# DDRSS0_PHY_CFG register map
Vendor: Texas Instruments
Registers are 32-bit, access per field, reset 0x0 unless marked. A register's access mark holds for its fields unless they carry their own. Offsets are as the file gives them; [hi:lo] are bit positions; lines under a group give offsets from that group; {n}, {i} and the like mark numbered series.

## DDRSS0_PHY_CFG (part 2 of 2)
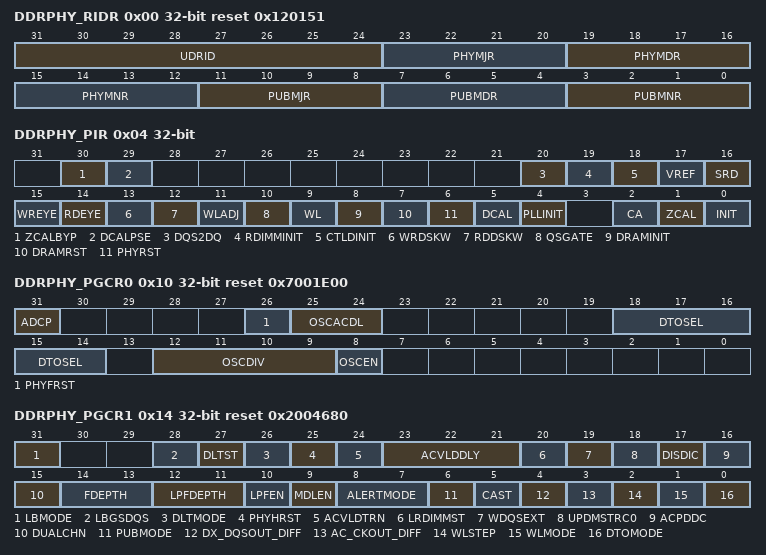
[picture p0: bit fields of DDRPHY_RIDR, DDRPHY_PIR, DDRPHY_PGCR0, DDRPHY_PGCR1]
0x00 DDRPHY_RIDR ro reset 0x120151 — Revision Identification Register
  [31:24] UDRID — User-Defined Revision ID
  [23:20] PHYMJR — PHY Major Revision
  [19:16] PHYMDR — PHY Moderate Revision
  [15:12] PHYMNR — PHY Minor Revision
  [11:8] PUBMJR — PUB Major Revision
  [7:4] PUBMDR — PUB Moderate Revision
  [3:0] PUBMNR — PUB Minor Revision
0x04 DDRPHY_PIR access not given — PHY Initialization Register
  [30] ZCALBYP — Impedance Calibration Bypass (access RW1C)
  [29] DCALPSE — Digital Delay Line (DDL) Calibration Pause (access RW1C)
  [20] DQS2DQ rw — Write DQS2DQ Training
  [19] RDIMMINIT rw — RDIMM Initialization
  [18] CTLDINIT rw — Controller DRAM Initialization
  [17] VREF rw — VREF Training
  [16] SRD rw — Static Read Training
  [15] WREYE rw — Write Data Eye Training
  [14] RDEYE rw — Read Data Eye Training
  [13] WRDSKW rw — Write Data Bit Deskew
  [12] RDDSKW rw — Read Data Bit Deskew
  [11] WLADJ rw — Write Leveling Adjust
  [10] QSGATE rw — Read DQS Gate Training
  [9] WL rw — Write Leveling
  [8] DRAMINIT rw — DRAM Initialization
  [7] DRAMRST rw — DRAM Reset (DDR3/DDR4/LPDDR4 Only)
  [6] PHYRST rw — PHY Reset
  [5] DCAL rw — Digital Delay Line (DDL) Calibration
  [4] PLLINIT rw — PLL Initialiazation
  [2] CA rw — CA Training
  [1] ZCAL rw — Impedance Calibration
  [0] INIT — Initialization Trigger (access RW1C)
0x10 DDRPHY_PGCR0 reset 0x7001E00 — PHY General Configuration Register 0
  [31] ADCP rw — Address Copy
  [26] PHYFRST rw — PHY FIFO Reset
  [25:24] OSCACDL rw — Oscillator Mode Address/Command Delay Line Select
  [18:14] DTOSEL rw — Digital Test Output Select
  [12:9] OSCDIV rw — Oscillator Mode Division
  [8] OSCEN rw — Oscillator Enable
0x14 DDRPHY_PGCR1 access not given reset 0x2004680 — PHY General Configuration Register 1
  [31] LBMODE rw — Loopback Mode
  [28] LBGSDQS — Load GSDQS LCDL with 2x the calibrated GSDQSPRD value (equivalent to one CK period) (access RW1C)
  [27] DLTST rw — Delay Line Test Start
  [26] DLTMODE rw — Delay Line Test Mode
  [25] PHYHRST rw — PHY High-Speed Reset
  [24] ACVLDTRN rw — AC Loopback Valid Train
  [23:21] ACVLDDLY rw — AC Loopback Valid Delay
  [20] LRDIMMST rw — LRDIMM Software Training
  [19] WDQSEXT rw — When WDQS Extension mode is enabled by setting this bit to 1'b1
  [18] UPDMSTRC0 rw — DFI Update Master Channel 0
  [17] DISDIC rw — Enable/Disable control for dfi_init_complete.
  [16] ACPDDC rw — AC Power-Down with Dual Channels
  [15] DUALCHN rw — Dual Channel Configuration
  [14:13] FDEPTH rw — Filter Depth
  [12:11] LPFDEPTH rw — Low-Pass Filter Depth
  [10] LPFEN rw — Low-Pass Filter Enable
  [9] MDLEN rw — Master Delay Line Enable
  [8:7] ALERTMODE rw — Control dfi_alert_n signal sent to the memory controller
  [6] PUBMODE rw — Enables, if set, the PUB to control the interface to the PHY and SDRAM.
  [5] CAST rw — CA Software Training.
  [4] DX_DQSOUT_DIFF rw — Selects PDIFF cell for DQS generation
  [3] AC_CKOUT_DIFF rw — Selects PDIFF cell for CK generation
  [2] WLSTEP rw — Write Leveling Step
  [1] WLMODE rw — Write Leveling (Software) Mode
  [0] DTOMODE rw — Digital Test Output Mode
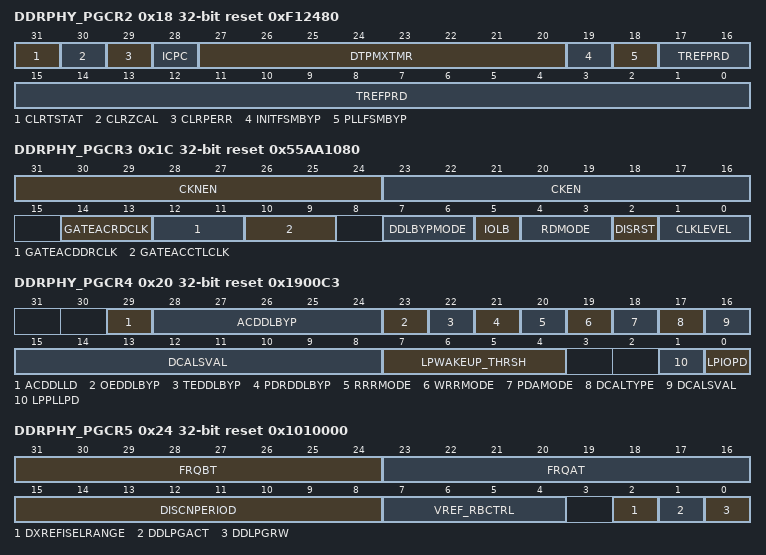
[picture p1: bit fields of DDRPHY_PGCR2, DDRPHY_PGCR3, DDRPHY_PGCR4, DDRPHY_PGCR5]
0x18 DDRPHY_PGCR2 access not given reset 0xF12480 — PHY General Configuration Register 2
  [31] CLRTSTAT — Clear Training Status Registers (access RW1C)
  [30] CLRZCAL — Clear Impedance Calibration (access RW1C)
  [29] CLRPERR — Clear Parity Error (access RW1C)
  [28] ICPC rw — Initialization Complete Pin Configuration
  [27:20] DTPMXTMR rw — Data Training PUB Mode Exit Timer
  [19] INITFSMBYP rw — Initialization Bypass
  [18] PLLFSMBYP rw — PLL FSM Bypass
  [17:0] TREFPRD rw — Refresh Period
0x1C DDRPHY_PGCR3 reset 0x55AA1080 — PHY General Configuration Register 3
  [31:24] CKNEN rw — CKN Enable
  [23:16] CKEN rw — CK Enable
  [14:13] GATEACRDCLK rw — Enable Clock Gating for AC [0] ctl_rd_clk
  [12:11] GATEACDDRCLK rw — Enable Clock Gating for AC [0] ddr_clk
  [10:9] GATEACCTLCLK rw — Enable Clock Gating for AC [0] ctl_clk
  [7:6] DDLBYPMODE rw — Controls DDL Bypass Modes
  [5] IOLB rw — IO Loop-Back Select
  [4:3] RDMODE rw — AC Receive FIFO Read Mode
  [2] DISRST rw — Read FIFO Reset Disable
  [1:0] CLKLEVEL rw — Clock Level when Clock Gating
0x20 DDRPHY_PGCR4 reset 0x1900C3 — PHY General Configuration Register 4
  [29] ACDDLLD rw — AC DDL Delay Select Dymainc Load
  [28:24] ACDDLBYP rw — AC DDL Bypass
  [23] OEDDLBYP rw — AC OE DDL Bypass
  [22] TEDDLBYP rw — AC ODT DDL Bypass
  [21] PDRDDLBYP rw — AC PDR DDL Bypass
  [20] RRRMODE rw — Read Path Rise-to-Rise Mode
  [19] WRRMODE rw — Write Path Rise-to-Rise Mode
  [18] PDAMODE rw — Set PDA mode timing
  [17] DCALTYPE rw — DDL Calibration Type
  [16:8] DCALSVAL rw — DDL Calibration Starting Value
  [7:4] LPWAKEUP_THRSH rw — AC Low Power Wakeup Threshold
  [1] LPPLLPD rw — AC Low Power PLL Power Down
  [0] LPIOPD rw — AC Low Power IO Power Down
0x24 DDRPHY_PGCR5 reset 0x1010000 — PHY General Configuration Register 5
  [31:24] FRQBT rw — Frequency B Ratio Term
  [23:16] FRQAT rw — Frequency A Ratio Term
  [15:8] DISCNPERIOD rw — DFI Disconnect Time Period
  [7:4] VREF_RBCTRL rw — Receiver bias core side control
  [2] DXREFISELRANGE rw — Internal VREF generator REFSEL ragne select
  [1] DDLPGACT rw — DDL Page Read Write select
  [0] DDLPGRW rw — DDL Page Read Write select
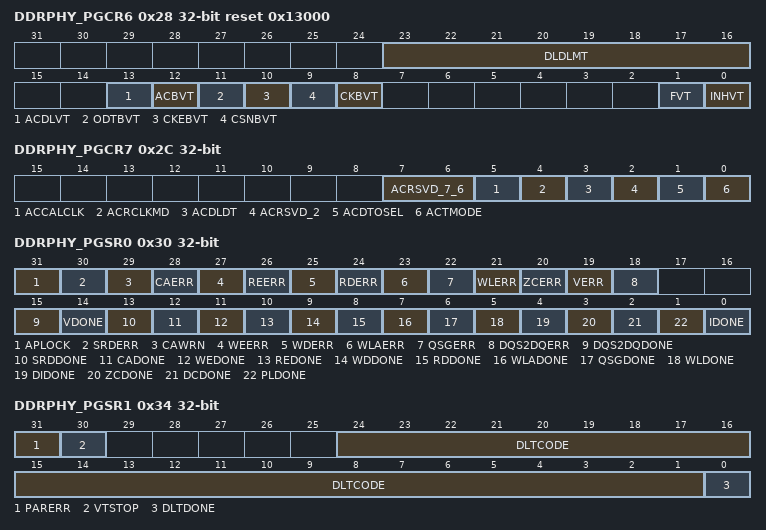
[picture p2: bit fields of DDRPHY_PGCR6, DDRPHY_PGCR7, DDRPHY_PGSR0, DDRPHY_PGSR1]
0x28 DDRPHY_PGCR6 reset 0x13000 — PHY General Configuration Register 6
  [23:16] DLDLMT rw — Delay Line VT Drift Limit
  [13] ACDLVT rw — AC Address/Command Delay LCDL VT Compensation
  [12] ACBVT rw — Address/Command Bit Delay VT Compensation
  [11] ODTBVT rw — ODT Bit Delay VT Compensation
  [10] CKEBVT rw — CKE Bit Delay VT Compensation
  [9] CSNBVT rw — CSN Bit Delay VT Compensation
  [8] CKBVT rw — CK Bit Delay VT Compensation
  [1] FVT rw — Forced VT Compensation Trigger
  [0] INHVT rw — VT Calculation Inhibit
0x2C DDRPHY_PGCR7 — PHY General Configuration Register 7
  [7:6] ACRSVD_7_6 rw — These bits are reserved for future AC special PHY modes but the registers are already connected to existing (unused) AC phy_mode bits.
  [5] ACCALCLK rw — AC Calibration Clock Select
  [4] ACRCLKMD rw — AC Read Clock Mode
  [3] ACDLDT rw — AC DDL Load Type
  [2] ACRSVD_2 rw — This bit is reserved for future AC special PHY modes but the register is already connected to existing (unused) AC phy_mode bits.
  [1] ACDTOSEL rw — AC Digital Test Output Select
  [0] ACTMODE rw — AC Test Mode
0x30 DDRPHY_PGSR0 ro — PHY General Status Register 0
  [31] APLOCK — AC PLL Lock
  [30] SRDERR — Static Read Error
  [29] CAWRN — CA Training Warning
  [28] CAERR — CA Training Error
  [27] WEERR — Write Eye Training Error
  [26] REERR — Read Eye Training Error
  [25] WDERR — Write Bit Deskew Error
  [24] RDERR — Read Bit Deskew Error
  [23] WLAERR — Write Leveling Adjustment Error
  [22] QSGERR — DQS Gate Training Error
  [21] WLERR — Write Leveling Error
  [20] ZCERR — Impedance Calibration Error
  [19] VERR — VREF Training Error
  [18] DQS2DQERR — Write DQS2DQ Training Error
  [15] DQS2DQDONE — Write DQS2DQ Training Done
  [14] VDONE — VREF Training Done
  [13] SRDDONE — Static Read Done
  [12] CADONE — CA Training Done
  [11] WEDONE — Write Eye Training Done
  [10] REDONE — Read Eye Training Done
  [9] WDDONE — Write Bit Deskew Done
  [8] RDDONE — Read Bit Deskew Done
  [7] WLADONE — Write Leveling Adjustment Done
  [6] QSGDONE — DQS Gate Training Done
  [5] WLDONE — Write Leveling Done
  [4] DIDONE — DRAM Initialization Done
  [3] ZCDONE — Impedance Calibration Done
  [2] DCDONE — Digital Delay Line (DDL) Calibration Done
  [1] PLDONE — PLL Lock Done
  [0] IDONE — Initialization Done
0x34 DDRPHY_PGSR1 ro — PHY General Status Register 1
  [31] PARERR — RDIMM Parity Error
  [30] VTSTOP
  [24:1] DLTCODE — Delay Line Test Code for AC macro 0
  [0] DLTDONE — Delay Line Test Done for AC macro 0
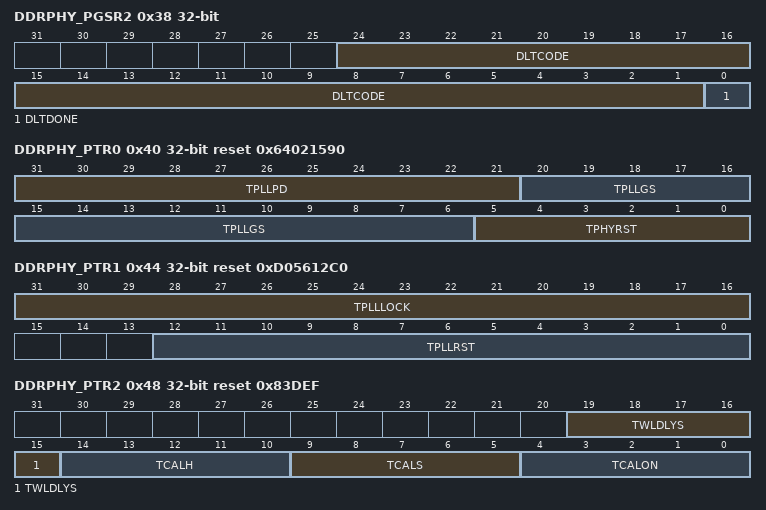
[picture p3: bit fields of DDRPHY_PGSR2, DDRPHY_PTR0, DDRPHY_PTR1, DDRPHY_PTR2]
0x38 DDRPHY_PGSR2 ro — PHY General Status Register 2
  [24:1] DLTCODE — Delay Line Test Code for AC macro 1
  [0] DLTDONE — Delay Line Test Done for AC macro 1
0x40 DDRPHY_PTR0 rw reset 0x64021590 — PHY Timing Register 0
  [31:21] TPLLPD — PLL Power-Down Time
  [20:6] TPLLGS — PLL Gear Shift Time
  [5:0] TPHYRST — PHY Reset Time
0x44 DDRPHY_PTR1 reset 0xD05612C0 — PHY Timing Register 1
  [31:16] TPLLLOCK rw — PLL Lock Time
  [12:0] TPLLRST rw — PLL Reset Time
0x48 DDRPHY_PTR2 reset 0x83DEF — PHY Timing Register 2
  [19:15] TWLDLYS rw — Write Leveling Delay Settling Time
  [14:10] TCALH rw — Calibration Hold Time
  [9:5] TCALS rw — Calibration Setup Time
  [4:0] TCALON rw — Calibration On Time
0x4C DDRPHY_PTR3 reset 0x411810 — PHY Timing Register 3
  [22:0] TDINIT0 rw — DRAM Initialization Time 0
0x50 DDRPHY_PTR4 reset 0x10AA — PHY Timing Register 4
  [12:0] TDINIT1 rw — DRAM Initialization Time 1
0x54 DDRPHY_PTR5 reset 0x68268 — PHY Timing Register 5
  [18:0] TDINIT2 rw — DRAM Initialization Time 1
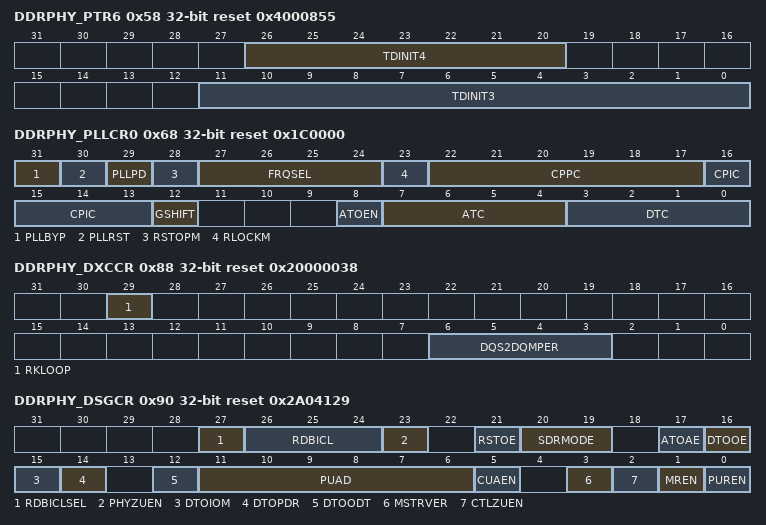
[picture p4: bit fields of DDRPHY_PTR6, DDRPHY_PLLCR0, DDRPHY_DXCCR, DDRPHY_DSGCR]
0x58 DDRPHY_PTR6 reset 0x4000855 — PHY Timing Register 6
  [26:20] TDINIT4 rw — DRAM Initialization Time 4
  [11:0] TDINIT3 rw — DRAM Initialization Time 3
0x68 DDRPHY_PLLCR0 reset 0x1C0000 — PLL Control Register 0 (Type B PLL Only)
  [31] PLLBYP rw — PLL Bypass
  [30] PLLRST rw — PLL Reset
  [29] PLLPD rw — PLL Power Down
  [28] RSTOPM rw — Reference Stop Mode
  [27:24] FRQSEL rw — PLL Frequency Select
  [23] RLOCKM rw — Relock Mode
  [22:17] CPPC rw — Charge Pump Proportional Current Control
  [16:13] CPIC rw — Charge Pump Integrating Current Control
  [12] GSHIFT rw — Gear Shift
  [8] ATOEN rw — Analog Test Enable
  [7:4] ATC rw — Analog Test Control
  [3:0] DTC rw — Digital Test Control
0x88 DDRPHY_DXCCR reset 0x20000038 — DATX8 Common Configuration Register
  [29] RKLOOP rw — Rank looping (per-rank eye centering) enable
  [6:3] DQS2DQMPER rw — Write DQS2DQ Training Measurement Period
0x90 DDRPHY_DSGCR reset 0x2A04129 — DDR System General Configuration Register
  [27] RDBICLSEL rw — When RDBI enabled, this bit is used to select RDBI CL calculation, if it is 1b1, calculation will use RDBICL, otherwise use default calculation.
  [26:24] RDBICL rw — When RDBI enabled, if RDBICLSEL is asserted, RDBI CL adjust using this value.
  [23] PHYZUEN rw — PHY Impedance Update Enable
  [21] RSTOE rw — SDRAM Reset Output Enable
  [20:19] SDRMODE rw — Single Data Rate Mode
  [17] ATOAE rw — ATO Analog Test Enable
  [16] DTOOE rw — DTO Output Enable
  [15] DTOIOM rw — DTO I/O Mode
  [14] DTOPDR rw — DTO Power Down Receiver
  [12] DTOODT rw — DTO On-Die Termination
  [11:6] PUAD rw — PHY Update Acknowledge Delay
  [5] CUAEN rw — Controller Update Acknowledge Enable
  [3] MSTRVER rw — Master Version
  [2] CTLZUEN rw — Controller Impedance Update Enable
  [1] MREN rw — Master Request Enable
  [0] PUREN rw — PHY Update Request Enable
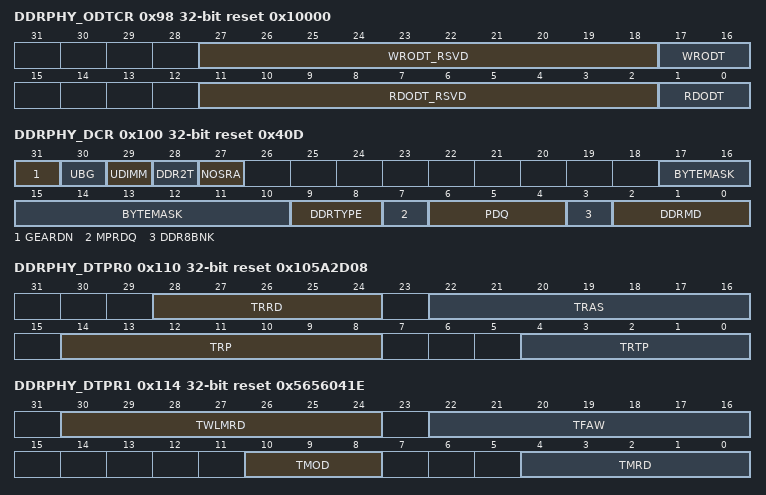
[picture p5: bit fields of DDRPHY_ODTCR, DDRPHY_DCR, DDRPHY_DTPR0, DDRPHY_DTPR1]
0x98 DDRPHY_ODTCR reset 0x10000 — ODT Configuration Register
  [27:18] WRODT_RSVD ro — Reserved.Return zeroes on reads.
  [17:16] WRODT rw — Write ODT.
  [11:2] RDODT_RSVD ro — Reserved.Return zeroes on reads.
  [1:0] RDODT rw — Read ODT.
0xC0 DDRPHY_GPR0 rw — General Purpose Register 0
0xC4 DDRPHY_GPR1 rw — General Purpose Register 1
0x100 DDRPHY_DCR reset 0x40D — DRAM Configuration Register
  [31] GEARDN rw — DDR4 Gear Down Timing.
  [30] UBG rw — Un-used Bank Group
  [29] UDIMM rw — Un-buffered DIMM Address Mirroring
  [28] DDR2T rw — DDR 2T Timing
  [27] NOSRA rw — No Simultaneous Rank Access
  [17:10] BYTEMASK rw
  [9:8] DDRTYPE rw
  [7] MPRDQ rw — Multi-Purpose Register (MPR) DQ (DDR3 Only)
  [6:4] PDQ rw — Primary DQ (DDR3 Only)
  [3] DDR8BNK rw — DDR8-Bank
  [2:0] DDRMD rw — DDR Mode
0x110 DDRPHY_DTPR0 reset 0x105A2D08 — DRAM Timing Parameters Register 0
  [28:24] TRRD rw — Activate to activate command delay (different banks)
  [22:16] TRAS rw — Activate to precharge command delay
  [14:8] TRP rw — Precharge command period
  [4:0] TRTP rw — Internal read to precharge command delay
0x114 DDRPHY_DTPR1 reset 0x5656041E — DRAM Timing Parameters Register 1
  [30:24] TWLMRD rw — Minimum delay from when write leveling mode is programmed to the first DQS/DQS# rising edge.
  [22:16] TFAW rw — 4-bank activate period
  [10:8] TMOD rw — Load mode update delay (DDR4 and DDR3 only)
  [4:0] TMRD rw — Load mode cycle time
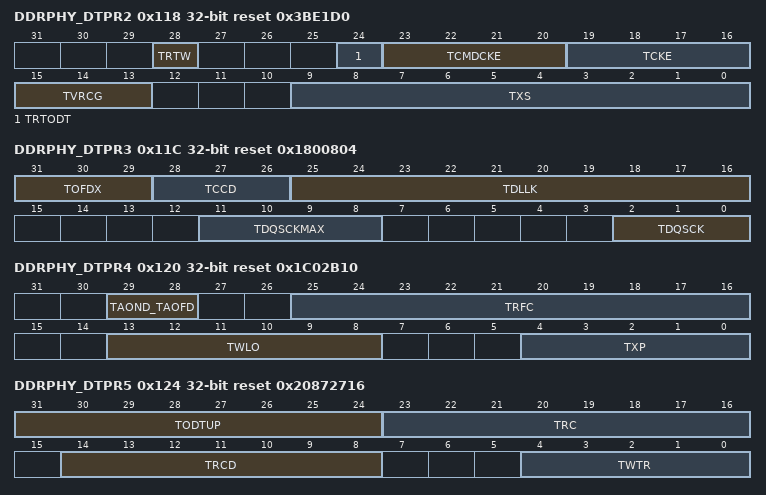
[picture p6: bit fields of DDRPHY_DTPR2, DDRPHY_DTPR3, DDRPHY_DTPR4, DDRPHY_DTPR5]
0x118 DDRPHY_DTPR2 reset 0x3BE1D0 — DRAM Timing Parameters Register 2
  [28] TRTW rw — Read to Write command delay.Valid values are
  [24] TRTODT rw — Read to ODT delay (DDR3 only)
  [23:20] TCMDCKE rw — Delay from Valid command to CKE Input low (LPDDR4 mode only)
  [19:16] TCKE rw — CKE minimum pulse width
  [15:13] TVRCG rw — tVRCG Enable.
  [9:0] TXS rw — Self refresh exit delay
0x11C DDRPHY_DTPR3 reset 0x1800804 — DRAM Timing Parameters Register 3
  [31:29] TOFDX rw — ODT turn-off delay extension
  [28:26] TCCD rw — Read to read and write to write command delay
  [25:16] TDLLK rw — DLL locking time
  [11:8] TDQSCKMAX rw — Maximum DQS output access time from CK/CK# (LPDDR2/3 only)
  [2:0] TDQSCK rw — DQS output access time from CK/CK# (LPDDR2/3 only)
0x120 DDRPHY_DTPR4 reset 0x1C02B10 — DRAM Timing Parameters Register 4
  [29:28] TAOND_TAOFD rw — ODT turn-on/turn-off delays (DDR2 only)
  [25:16] TRFC rw — Refresh-to-Refresh
  [13:8] TWLO rw — Write leveling output delay
  [4:0] TXP rw — Power down exit delay
0x124 DDRPHY_DTPR5 reset 0x20872716 — DRAM Timing Parameters Register 5
  [31:24] TODTUP rw — ODT CA Value Update Time
  [23:16] TRC rw — Activate to activate command delay (same bank)
  [14:8] TRCD rw — Activate to read or write delay
  [4:0] TWTR rw — Internal write to read command delay
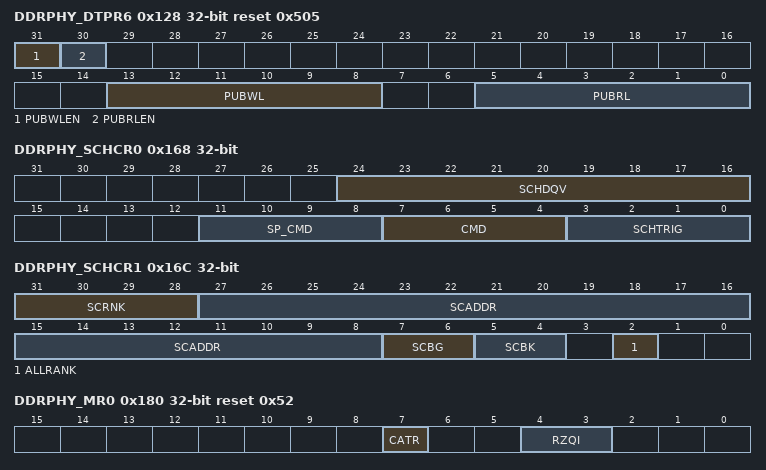
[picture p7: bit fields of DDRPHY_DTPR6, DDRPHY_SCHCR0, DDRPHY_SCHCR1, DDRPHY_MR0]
0x128 DDRPHY_DTPR6 reset 0x505 — DRAM Timing Parameters Register 6
  [31] PUBWLEN rw — PUB Write Latency Enable
  [30] PUBRLEN rw — PUB Read Latency Enable
  [13:8] PUBWL rw — Write Latency
  [5:0] PUBRL rw — Read Latency
0x168 DDRPHY_SCHCR0 access not given — Scheduler Command Register 0
  [24:16] SCHDQV rw — Scheduler Command DQ Value
  [11:8] SP_CMD rw — Special Command codes
  [7:4] CMD rw — Specifies the Command to be issued
  [3:0] SCHTRIG — Mode Register Command Trigger (access RW1C)
0x16C DDRPHY_SCHCR1 — Scheduler Command Register 1
  [31:28] SCRNK rw — Scheduler Rank Address
  [27:8] SCADDR rw — Scheduler Command Address Specifies the value to be driven on the address bus.
  [7:6] SCBG rw — Scheduler Command Bank Group
  [5:4] SCBK rw — Scheduler Command Bank Address
  [2] ALLRANK rw — All Ranks enabled
0x180 DDRPHY_MR0 reset 0x52 — LPDDR4 Mode Register 0
  [7] CATR rw — CA Terminating Rank
  [4:3] RZQI rw — Built-in Self-Test for RZQ
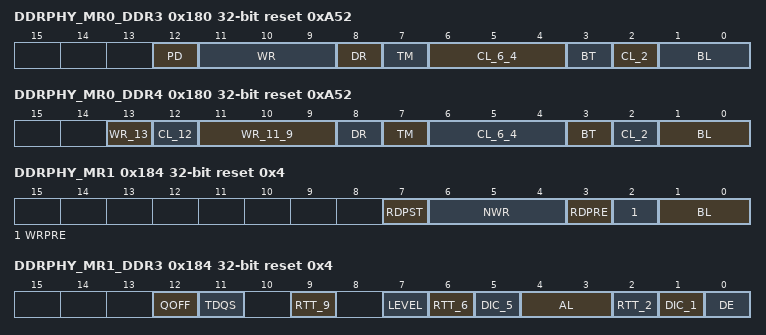
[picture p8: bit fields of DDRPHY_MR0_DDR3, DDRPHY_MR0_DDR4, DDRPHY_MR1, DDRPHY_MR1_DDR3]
0x180 DDRPHY_MR0_DDR3 reset 0xA52 — DDR3 Mode Register 0
  [12] PD rw — Power-Down Control
  [11:9] WR rw — Write Recovery and Read to Precharge
  [8] DR rw — DLL Reset
  [7] TM rw — Operating Mode
  [6:4] CL_6_4 rw — CAS Latency
  [3] BT rw — Burst Type
  [2] CL_2 rw — CAS Latency
  [1:0] BL rw — Burst Length
0x180 DDRPHY_MR0_DDR4 reset 0xA52 — DDR4 Mode Register 0
  [13] WR_13 rw — Write Recovery and Read to Precharge
  [12] CL_12 rw — CAS Latency
  [11:9] WR_11_9 rw — Write Recovery and Read to Precharge
  [8] DR rw — DLL Reset
  [7] TM rw — Operating Mode
  [6:4] CL_6_4 rw — CAS Latency
  [3] BT rw — Burst Type
  [2] CL_2 rw — CAS Latency
  [1:0] BL rw — Burst Length
0x184 DDRPHY_MR1 reset 0x4 — LPDDR4 Mode Register 1
  [7] RDPST rw — Read Postamble Length
  [6:4] NWR rw — Write-recovery for auto-precharge command
  [3] RDPRE rw — Read Preamble Length
  [2] WRPRE rw — Write Preamble Length
  [1:0] BL rw — Burst Length
0x184 DDRPHY_MR1_DDR3 reset 0x4 — DDR3 Mode Register 1
  [12] QOFF rw — Output Enable/Disable
  [11] TDQS rw — Termination Data Strobe
  [9] RTT_9 rw — On Die Termination
  [7] LEVEL rw — Write Leveling Enable
  [6] RTT_6 rw — On Die Termination
  [5] DIC_5 rw — Output Driver Impedance Control
  [4:3] AL rw — Posted CAS Additive Latency
  [2] RTT_2 rw — On Die Termination
  [1] DIC_1 rw — Output Driver Impedance Control
  [0] DE rw — DLL Enable/Disable
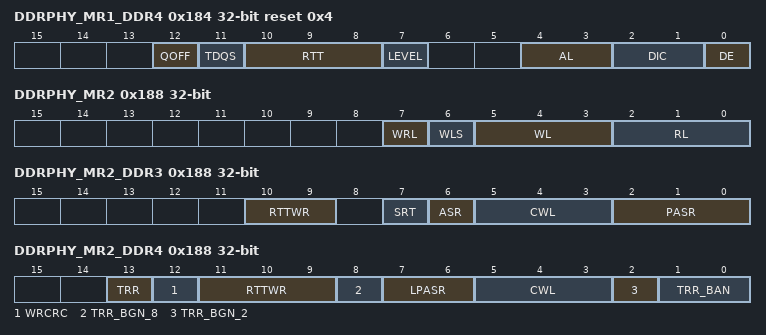
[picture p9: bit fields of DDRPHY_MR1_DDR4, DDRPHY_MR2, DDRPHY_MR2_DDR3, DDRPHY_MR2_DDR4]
0x184 DDRPHY_MR1_DDR4 reset 0x4 — DDR4 Mode Register 1
  [12] QOFF rw — Output Enable/Disable
  [11] TDQS rw — Termination Data Strobe
  [10:8] RTT rw — On Die Termination
  [7] LEVEL rw — Write Leveling Enable
  [4:3] AL rw — Posted CAS Additive Latency
  [2:1] DIC rw — Output Driver Impedance Control
  [0] DE rw — DLL Enable/Disable
0x188 DDRPHY_MR2 — LPDDR4 Mode Register 2
  [7] WRL rw — Write Leveling
  [6] WLS rw — Write Latency Set
  [5:3] WL rw — Write Latency
  [2:0] RL rw — Read Latency
0x188 DDRPHY_MR2_DDR3 — DDR3 Mode Register 2
  [10:9] RTTWR rw — Dynamic ODT
  [7] SRT rw — Self-Refresh Temperature Range
  [6] ASR rw — Auto Self-Refresh
  [5:3] CWL rw — CAS Write Latency
  [2:0] PASR rw — Partial Array Self Refresh
0x188 DDRPHY_MR2_DDR4 — DDR4 Mode Register 2
  [13] TRR rw — TRR Mode setting
  [12] WRCRC rw — Write CRC.When 1b1, CRC is enabled for write operation.
  [11:9] RTTWR rw — Dynamic ODT
  [8] TRR_BGN_8 rw — Defines the bank group (BGn) to which TRR will be applied
  [7:6] LPASR rw — Low Power Array Self Refresh (LP ASR)
  [5:3] CWL rw — CAS Write Latency
  [2] TRR_BGN_2 rw — Define the bank group (BGn) to which TRR will be applied
  [1:0] TRR_BAN rw — Define which bank (BAn) the target row is located
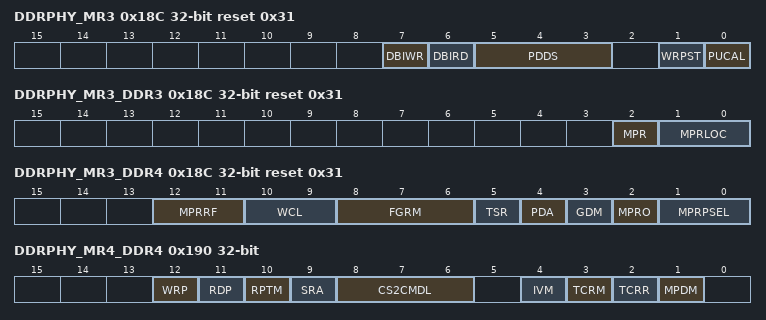
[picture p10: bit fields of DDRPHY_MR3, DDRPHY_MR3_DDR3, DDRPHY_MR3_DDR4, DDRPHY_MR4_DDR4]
0x18C DDRPHY_MR3 reset 0x31 — LPDDR4 Mode Register 3
  [7] DBIWR rw — DBI-Write Enable
  [6] DBIRD rw — DBI-Read Enable
  [5:3] PDDS rw — Pull-down Drive Strength
  [1] WRPST rw — Write Postamble Length
  [0] PUCAL rw — Pull-up Calibration Point
0x18C DDRPHY_MR3_DDR3 reset 0x31 — DDR3 Mode Register 3
  [2] MPR rw — Multi-Purpose Register Enable
  [1:0] MPRLOC rw — Multi-Purpose Register (MPR) Location
0x18C DDRPHY_MR3_DDR4 reset 0x31 — DDR4 Mode Register 3
  [12:11] MPRRF rw — Multi-Purpose Register Read Format
  [10:9] WCL rw — Write Command Latency when CRC and DM are enabled
  [8:6] FGRM rw — Fine Granularity Refresh Mode
  [5] TSR rw — Temp sensor readout
  [4] PDA rw — Per DRAM Addressability
  [3] GDM rw — Geardown Mode
  [2] MPRO rw — Multi-Purpose Operation
  [1:0] MPRPSEL rw — Multi-Purpose Register (MPR) Page Selection
{0x180+4i} DDRPHY_MR{i} (i=4..7) — LPDDR4 Mode Register {i}
0x190 DDRPHY_MR4_DDR3 — DDR3 Mode Register 4
0x190 DDRPHY_MR4_DDR4 — DDR4 Mode Register 4
  [12] WRP rw — Write Preamble
  [11] RDP rw — Read Preamble
  [10] RPTM rw — Read Preamble Training Mode
  [9] SRA rw — Self Refresh Abort
  [8:6] CS2CMDL rw — CS to Command Latency Mode
  [4] IVM rw — Internal VREF Monitor
  [3] TCRM rw — Temperature Controlled Refresh Mode
  [2] TCRR rw — Temperature Controlled Refresh Range
  [1] MPDM rw — Maximum Power Down Mode
0x194 DDRPHY_MR5_DDR3 reset 0x400 — DDR3 Mode Register 5
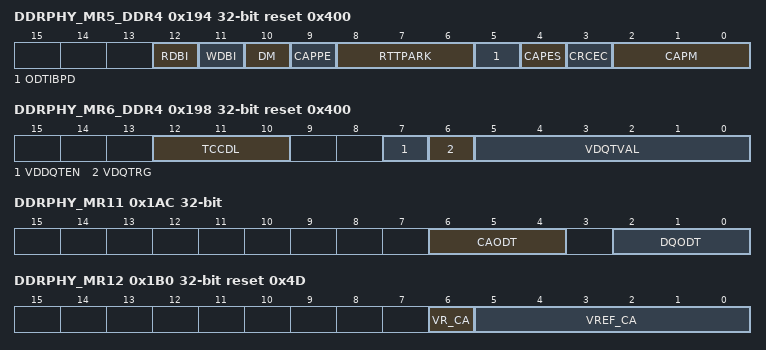
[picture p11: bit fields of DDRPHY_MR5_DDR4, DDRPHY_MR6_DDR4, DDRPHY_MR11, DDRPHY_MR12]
0x194 DDRPHY_MR5_DDR4 reset 0x400 — DDR4 Mode Register 5
  [12] RDBI rw — Read DBI
  [11] WDBI rw — Write DBI
  [10] DM rw — Data Mask
  [9] CAPPE rw — CA Parity Persistent Error
  [8:6] RTTPARK rw
  [5] ODTIBPD rw — ODT Input Buffer during Power Down mode
  [4] CAPES rw — C/A Parity Error Status
  [3] CRCEC rw — CRC Error Clear
  [2:0] CAPM rw — C/A Parity Latency Mode
0x198 DDRPHY_MR6_DDR3 reset 0x400 — DDR3 Mode Register 6
0x198 DDRPHY_MR6_DDR4 reset 0x400 — DDR4 Mode Register 6
  [12:10] TCCDL rw — CAS_n to CAS_n command delay for same bank group (tCCD_L)
  [7] VDDQTEN rw — VrefDQ Training Enable
  [6] VDQTRG rw — VrefDQ Training Range
  [5:0] VDQTVAL rw — VrefDQ Training Values
0x19C DDRPHY_MR7_DDR3 — LPDDR2 Mode Register 7
0x19C DDRPHY_MR7_DDR4 — DDR4 Mode Register 7
  [15:0] RSVD_15_0 rw — Reserve for future use.
0x1AC DDRPHY_MR11 — LPDDR4 Mode Register 11
  [6:4] CAODT rw — CA Bus Receiver On-Die-Termination
  [2:0] DQODT rw — DQ Bus Receiver On-Die-Termination
0x1AC DDRPHY_MR11_DDR3 — DDR3 Mode Register 11
0x1AC DDRPHY_MR11_DDR4 — DDR4 Mode Register 11
0x1B0 DDRPHY_MR12 reset 0x4D — LPDDR4 Mode Register 12
  [6] VR_CA rw — VREF_CA Range Select.
  [5:0] VREF_CA rw — Controls the VREF(ca) levels for Frequency-Set-Point[1:0].
0x1B0 DDRPHY_MR12_DDR3 reset 0x4D — DDR3 Mode Register 12
0x1B0 DDRPHY_MR12_DDR4 reset 0x4D — DDR4 Mode Register 12
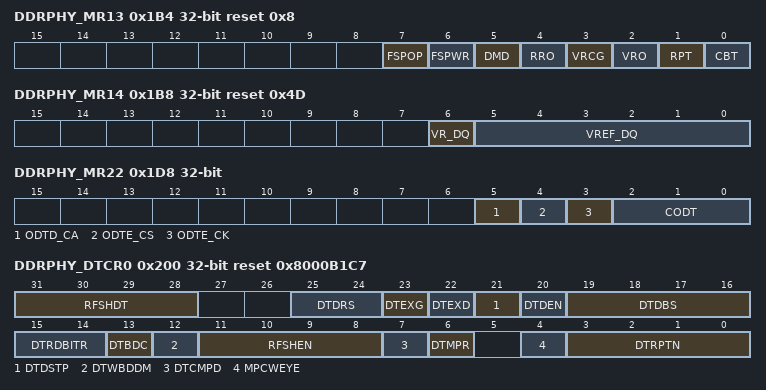
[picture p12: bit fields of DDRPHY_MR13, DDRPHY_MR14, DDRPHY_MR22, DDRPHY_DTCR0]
0x1B4 DDRPHY_MR13 reset 0x8 — LPDDR4 Mode Register 13
  [7] FSPOP rw — Frequency Set Point Operation Mode
  [6] FSPWR rw — Frequency Set Point Write Enable
  [5] DMD rw — Data Mask Enable
  [4] RRO rw — Refresh Rate Option
  [3] VRCG rw — VREF Current Generator
  [2] VRO rw — VREF Output
  [1] RPT rw — Read Preamble Training Mode
  [0] CBT rw — Command Bus Training
0x1B4 DDRPHY_MR13_DDR3 reset 0x8 — DDR3 Mode Register 13
0x1B4 DDRPHY_MR13_DDR4 reset 0x8 — DDR4 Mode Register 13
0x1B8 DDRPHY_MR14 reset 0x4D — LPDDR4 Mode Register 14
  [6] VR_DQ rw — VREFDQ Range Selects.
  [5:0] VREF_DQ rw — Reserved.Return zeroes on reads.
0x1B8 DDRPHY_MR14_DDR3 reset 0x4D — DDR3 Mode Register 14
0x1B8 DDRPHY_MR14_DDR4 reset 0x4D — DDR4 Mode Register 14
0x1D8 DDRPHY_MR22 — LPDDR4 Mode Register 22
  [5] ODTD_CA rw — CA ODT termination disable.
  [4] ODTE_CS rw — ODT CS override.
  [3] ODTE_CK rw — ODT CK override.
  [2:0] CODT rw — Controller ODT value for VOH calibration.
0x1D8 DDRPHY_MR22_DDR3 — DDR3 Mode Register 22
0x1D8 DDRPHY_MR22_DDR4 — DDR4 Mode Register 22
0x200 DDRPHY_DTCR0 access not given reset 0x8000B1C7 — Data Training Configuration Register 0
  [31:28] RFSHDT rw — Refresh During Training
  [25:24] DTDRS rw — Data Training Debug Rank Select
  [23] DTEXG rw — Data Training with Early/Extended Gate
  [22] DTEXD rw — Data Training Extended Write DQS
  [21] DTDSTP — Data Training Debug Step (access RW1C)
  [20] DTDEN rw — Data Training Debug Enable
  [19:16] DTDBS rw — Data Training Debug Byte Select
  [15:14] DTRDBITR rw — Data Training read DBI deskewing configuration
  [13] DTBDC rw — Data Training Bit Deskew Centering
  [12] DTWBDDM rw — Data Training Write Bit Deskew Data Mask
  [11:8] RFSHEN rw — Refreshes Issued During Entry to Training
  [7] DTCMPD rw — Data Training Compare Data
  [6] DTMPR rw — Data Training Using MPR
  [4] MPCWEYE rw — WEYE Training using MPC FIFO Commands
  [3:0] DTRPTN rw — Data Training Repeat Number
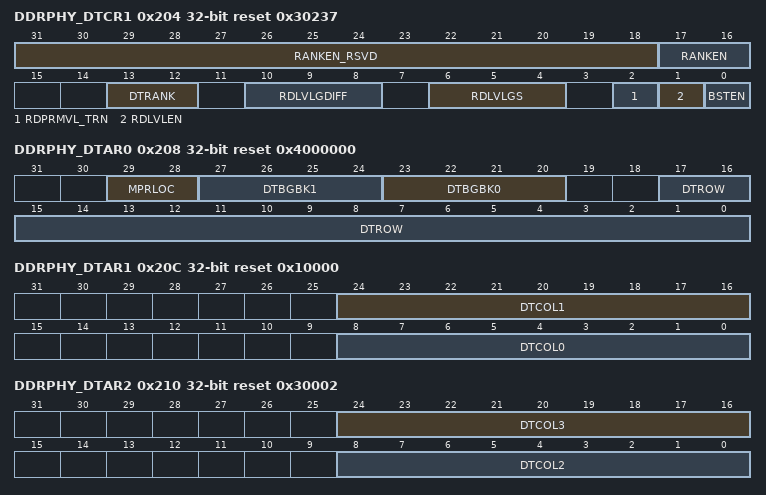
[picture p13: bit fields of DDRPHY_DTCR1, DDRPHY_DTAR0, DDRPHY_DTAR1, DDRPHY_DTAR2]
0x204 DDRPHY_DTCR1 reset 0x30237 — Data Training Configuration Register 1
  [31:18] RANKEN_RSVD ro — Rank Enable.
  [17:16] RANKEN rw — Rank Enable.
  [13:12] DTRANK rw — Data Training Rank
  [10:8] RDLVLGDIFF rw — Read Leveling Gate Sampling Difference
  [6:4] RDLVLGS rw — Read Leveling Gate Shift
  [2] RDPRMVL_TRN rw — Read Preamble Training enable
  [1] RDLVLEN rw — Read Leveling Enable
  [0] BSTEN rw — Basic Gate Training Enable
0x208 DDRPHY_DTAR0 reset 0x4000000 — Data Training Address Register 0
  [29:28] MPRLOC rw — Multi-Purpose Register (MPR) Location
  [27:24] DTBGBK1 rw — Data Training Bank Group and Bank Address
  [23:20] DTBGBK0 rw — Data Training Bank Group and Bank Address
  [17:0] DTROW rw — Data Training Row Address
0x20C DDRPHY_DTAR1 reset 0x10000 — Data Training Address Register 1
  [24:16] DTCOL1 rw — Data Training Column Address
  [8:0] DTCOL0 rw — Data Training Column Address
0x210 DDRPHY_DTAR2 reset 0x30002 — Data Training Address Register 2
  [24:16] DTCOL3 rw — Data Training Column Address
  [8:0] DTCOL2 rw — Data Training Column Address
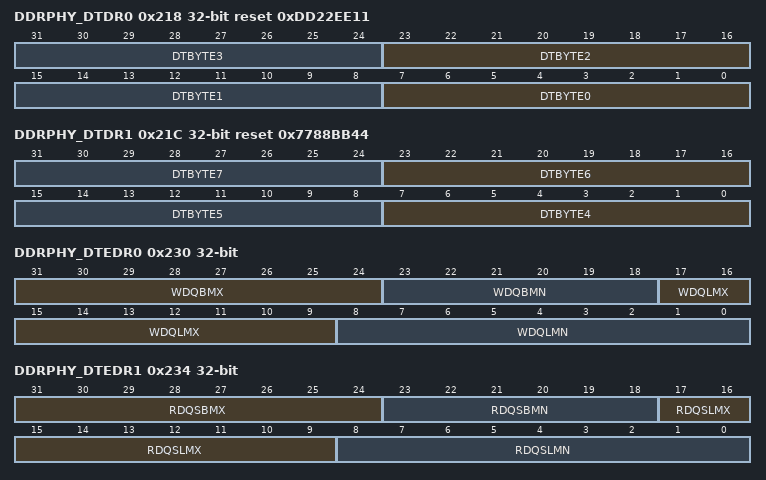
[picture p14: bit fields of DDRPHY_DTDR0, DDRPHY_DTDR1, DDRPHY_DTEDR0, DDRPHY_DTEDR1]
0x218 DDRPHY_DTDR0 rw reset 0xDD22EE11 — Data Training Data Register 0
  [8n+7:8n] DTBYTE{n} (n=0..3) — Data Training Data
0x21C DDRPHY_DTDR1 rw reset 0x7788BB44 — Data Training Data Register 1
  [8n-25:8n-32] DTBYTE{n} (n=4..7) — Data Training Data
0x230 DDRPHY_DTEDR0 ro — Data Training Eye Data Register 0
  [31:24] WDQBMX — Data Training Write BDL Shift Maximum.
  [23:18] WDQBMN — Data Training Write BDL Shift Minimum.
  [17:9] WDQLMX — Data Training WDQ LCDL Maximum.
  [8:0] WDQLMN — Data Training WDQ LCDL Minimum.
0x234 DDRPHY_DTEDR1 ro — Data Training Eye Data Register 1
  [31:24] RDQSBMX — Data Training Read BDL Shift Maximum.
  [23:18] RDQSBMN — Data Training Read BDL Shift Minimum.
  [17:9] RDQSLMX — Data Training RDQS LCDL Maximum.
  [8:0] RDQSLMN — Data Training RDQS LCDL Minimum.
0x238 DDRPHY_DTEDR2 ro — Data Training Eye Data Register 2
  [31:24] RDQSNBMX — Data Training Read BDL Shift Maximum.
  [23:18] RDQSNBMN — Data Training Read BDL Shift Minimum.
  [17:9] RDQSNLMX — Data Training RDQSN LCDL Maximum.
  [8:0] RDQSNLMN — Data Training RDQSN LCDL Minimum.
0x23C DDRPHY_VTDR ro reset 0x7F003F00 — VREF Training Data Register
  [30:24] HVREFMX — DRAM DQ VREF Maximum.
  [22:16] HVREFMN — DRAM DQ VREF Minimum.
  [13:8] DVREFMX — DRAM DQ VREF Maximum.
  [5:0] DVREFMN — DRAM DQ VREF Minimum.
0x248 DDRPHY_PGCR8 reset 0x300AA — PHY General Configuration Register 8
  [31:28] INC_DQS2DQ_CF rw — Counter Cycles Factor
  [27:20] INC_DQS2DQ_CM rw — Counter Cycle Multiplier
  [19:18] INC_DQS2DQ_RANKEN_RSVD ro — Rank Enable
  [17:16] INC_DQS2DQ_RANKEN rw — Rank Enable
  [15] INC_DQS2DQ_MODE rw — Self Incremental DQS2DQ Training
  [14] INC_DQS2DQ_EN rw — Incremental DQS2DQ Training
  [8:0] BSWAPMSB rw — When a bit is set, it indicates that the corresponding PHY byte lane is connected to MSByte of the LPDDR4 DRAM 16 bit instance it is connected to.
0x250 DDRPHY_DQSDR0 reset 0x88000 — DQS Drift Register 0
  [31:28] DFTDLY rw — Number of delay taps by which the DQS gate LCDL will be updated when DQS drift is detected
  [27] DFTZQUP rw — Drift Impedance Update
  [26] DFTDDLUP rw — Drift DDL Update
  [21:20] DFTRDSPC rw — Drift Read Spacing
  [19:16] DFTB2BRD rw — Drift Back-to-Back Reads
  [15:12] DFTIDLRD rw — Drift Idle Reads
  [7:4] DFTGPULSE rw — Gate Pulse Enable
  [3:2] DFTUPMODE rw — DQS Drift Update Mode
  [1] DFTDTMODE rw — DQS Drift Detection Mode
  [0] DFTDTEN rw — DQS Drift Detection Enable
0x254 DDRPHY_DQSDR1 rw reset 0xA8000000 — DQS Drift Register 1
  [31:29] DFTUPDACKF — Drift DFI Update Request ACK to DQS Drift FSM issing IDLE REad Cycles Factor
  [28:24] DFTUPDACKC — Drift DFI Update ACK to DQS Drift FSM issuing IDLE Read Cycles
  [23:20] DFTRDB2BF — Drift Back-to-Back Read Cycles Factor
  [19:16] DFTRDIDLF — Drift Idle Read Cycles Factor
  [15:8] DFTRDB2BC — Drift Back-to-Back Read Cycles
  [7:0] DFTRDIDLC — Drift Idle Read Cycles
0x258 DDRPHY_DQSDR2 — DQS Drift Register 2
  [23:16] DFTTHRSH rw — Drift Threshold
  [15:0] DFTMNTPRD rw — Drift Monitor Period
0x400 DDRPHY_BISTRR reset 0x780000 — BIST Run Register
  [29] BPRBST rw — BIST PRBS Type.
  [28] BSOMA rw — BIST Stop on Maximum Address
  [27:26] BACDPAT rw — BIST AC Data Pattern
  [25] BCCSEL rw — BIST Clock Cycle Select
  [24:23] BCKSEL rw — BIST CK Select
  [22:19] BDXSEL rw — BIST DATX8 Select
  [18:17] BDXDPAT rw — BIST Data Pattern
  [16] BDMEN rw — BIST Data Mask Enable
  [15] BACEN rw — BIST AC Enable
  [14] BDXEN rw — BIST DATX8 Enable
  [13] BSONF rw — BIST Stop On Nth Fail
  [12:5] NFAIL rw — Number of Failures
  [4] BINF rw — BIST Infinite Run
  [3] BMODE rw — BIST Mode
  [2:0] BINST rw — BIST Instruction
0x404 DDRPHY_BISTWCR rw reset 0x200020 — BIST Word Count Register
  [31:16] BACWCNT — BIST AC Word Count
  [15:0] BDXWCNT — BIST DX Word Count
0x408 DDRPHY_BISTMSKR0 — BIST Mask Register 0
  [31:22] CSMSK_RSVD ro — Reserved.Return zeros on reads.
  [21:20] CSMSK rw — Mask bit for each of the up to 12 CS_N bits.
  [19] ACTMSK rw — Mask bit for the RAS.
  [17:0] AMSK rw — Mask bit for each of the up to 16 address bits.
0x40C DDRPHY_BISTMSKR1 — BIST Mask Register 1
  [31:28] DMMSK rw — Mask bit for the data mask (DM) bit.
  [27] PARINMSK rw — Mask bit for the PAR_IN.
  [26:25] CIDMSK_RSVD ro — Reserved.Return zeros on reads.
  [24] CIDMSK rw — Mask bits for each of the up to 3 Chip IP bits.
  [23:18] ODTMSK_RSVD ro — Reserved.Return zeros on reads.
  [17:16] ODTMSK rw — Mask bit for each of the up to 8 ODT bits.
  [15:10] CKEMSK_RSVD ro — Reserved.Return zeros on reads.
  [9:8] CKEMSK rw — Mask bit for each of the up to 8 CKE bits.
  [7:4] BAMSK rw — Mask bit for each of the up to 4 bank address bits.
0x410 DDRPHY_BISTMSKR2 rw — BIST Mask Register 2
  [31:0] DQMSK — Mask bit for each of the 8 data (DQ) bits
0x414 DDRPHY_BISTLSR rw reset 0x1234ABCD — BIST LFSR Seed Register
  [31:0] SEED — LFSR seed for pseudo-random BIST patterns
0x418 DDRPHY_BISTAR0 — BIST Address Register 0
  [31:28] BBANK rw — BIST Bank Address
  [11:0] BCOL rw — BIST Column Address
0x41C DDRPHY_BISTAR1 reset 0xF0000 — BIST Address Register 1
  [19:16] BMRANK rw — BIST Maximum Rank
  [15:4] BAINC rw — BIST Address Increment
  [3:0] BRANK rw — BIST Rank
0x420 DDRPHY_BISTAR2 reset 0xF0000FFF — BIST Address Register 2
  [31:28] BMBANK rw — BIST Maximum Bank Address
  [11:0] BMCOL rw — BIST Maximum Column Address
0x424 DDRPHY_BISTAR3 — BIST Address Register 3
  [17:0] BROW rw — BIST Row Address
0x428 DDRPHY_BISTAR4 reset 0x3FFFF — BIST Address Register 4
  [17:0] BMROW rw — BIST Maximum Row Address
0x42C DDRPHY_BISTUDPR rw reset 0xFFFF0000 — BIST User Data Pattern Register
  [31:16] BUDP1 — BIST User Data Pattern 1
  [15:0] BUDP0 — BIST User Data Pattern 0
0x430 DDRPHY_BISTGSR ro — BIST General Status Register
  [29:28] RASBER — RAS_n/ACT_n Bit Error
  [27:20] DMBER — DM Bit Error
  [10:2] BDXERR — BIST Data Error
  [1] BACERR — BIST Address/Command Error
  [0] BDONE — BIST Done
0x434 DDRPHY_BISTWER0 ro — BIST Word Error Register 0
  [17:0] ACWER — Address/Command Word Error
0x438 DDRPHY_BISTWER1 ro — BIST Word Error Register 1
  [15:0] DXWER — Byte Word Error
0x43C DDRPHY_BISTBER0 ro — BIST Bit Error Register 0
  [31:0] ABER — Address Bit Error
0x440 DDRPHY_BISTBER1 ro — BIST Bit Error Register 1
  [31:12] CSBER_RSVD — Reserved.Return zeros on reads.
  [11:8] CSBER — CS_N Bit Error.
  [7:0] BABER — Bank Address Bit Error
0x444 DDRPHY_BISTBER2 ro — BIST Bit Error Register 2
  [31:0] DQBER0 — Data Bit Error
0x448 DDRPHY_BISTBER3 ro — BIST Bit Error Register 3
  [31:0] DQBER1 — Data Bit Error
0x44C DDRPHY_BISTBER4 ro — BIST Bit Error Register 4
  [13:10] CIDBER_RSVD — Reserved.Return zeros on reads.
  [9:8] CIDBER — Chip ID Bit Error.
  [3:0] ABER — Address Bit Error
0x450 DDRPHY_BISTWCSR ro — BIST Word Count Status Register
  [31:16] DXWCNT — Byte Word Count
  [15:0] ACWCNT — Address/Command Word Count
0x454 DDRPHY_BISTFWR0 ro — BIST Fail Word Register 0
  [31:22] CSWEBS_RSVD — Reserved.Return zeros on reads.
  [21:20] CSWEBS — Bit status during a word error for each of the up to 12 CS# bits.
  [18] ACTWEBS — Bit status during a word error for the RAS.
  [17:0] AWEBS — Bit status during a word error for each of the up to 16 address bits
0x458 DDRPHY_BISTFWR1 ro — BIST Fail Word Register 1
  [31:28] DMWEBS — Bit status during a word error for the data mask (DM) bit
  [22:21] CIDWEBS_RSVD — Reserved.Return zeros on reads.
  [20] CIDWEBS — Bit status during a word error for each of the up to 3 chip ID bits.
  [19:16] BAWEBS — Bit status during a word error for each of the bank address bits
  [15:10] ODTWEBS_RSVD — Reserved.Return zeros on reads.
  [9:8] ODTWEBS — Bit status during a word error for each of the up to 8 ODT bits.
  [7:2] CKEWEBS_RSVD — Reserved.Return zeros on reads.
  [1:0] CKEWEBS — Bit status during a word error for each of the up to 8 CKE bits.
0x45C DDRPHY_BISTFWR2 ro — BIST Fail Word Register 2
  [31:0] DQWEBS — Bit status during a word error for each of the 8 data (DQ) bits
0x460 DDRPHY_BISTBER5 ro — BIST Bit Error Register 5
  [31:20] ODTBER_RSVD — Reserved.Return zeros on reads.
  [19:16] ODTBER — ODT Bit Error.
  [15:4] CKEBER_RSVD — Reserved.Return zeros on reads.
  [3:0] CKEBER — CKE Bit Error.
0x4DC DDRPHY_RANKIDR — Rank ID Register
  [19:16] RANKRID rw — Rank Read ID
  [3:0] RANKWID rw — Rank Write ID
0x4E0 DDRPHY_RIOCR0 ro — Rank I/O Configuration Register 0
0x4E4 DDRPHY_RIOCR1 ro — Rank I/O Configuration Register 1
0x4E8 DDRPHY_RIOCR2 — Rank I/O Configuration Register 2
  [29:26] COEMODE_RSVD ro — Reserved.Return zeros on reads.
  [25:24] COEMODE rw — SDRAM C Output Enable (OE) Mode Selection.
  [23:4] CSOEMODE_RSVD ro — Reserved.Return zeros on reads.
  [3:0] CSOEMODE rw — SDRAM CS_n Output Enable (OE) Mode Selection.
0x4EC DDRPHY_RIOCR3 ro — Rank I/O Configuration Register 3
0x4F0 DDRPHY_RIOCR4 reset 0x5 — Rank I/O Configuration Register 4
  [15:4] CKEOEMODE_RSVD ro — Reserved.Return zeros on reads.
  [3:0] CKEOEMODE rw — SDRAM CKE Output Enable (OE) Mode Selection.
0x4F4 DDRPHY_RIOCR5 reset 0x5 — Rank I/O Configuration Register 5
  [15:4] ODTOEMODE_RSVD ro — Reserved.Return zeros on reads.
  [3:0] ODTOEMODE rw — SDRAM On-die Termination Output Enable (OE) Mode Selection.
0x500 DDRPHY_ACIOCR0 reset 0x30070000 — AC I/O Configuration Register 0
  [31:30] ACSR rw — Address/Command Slew Rate (D3F I/O Only)
  [29] RSTIOM rw — SDRAM Reset I/O Mode
  [28] RSTPDR rw — SDRAM Reset Power Down Receiver
  [26] RSTODT rw — SDRAM Reset On-Die Termination
  [23:16] ESR rw — Decoupling Capacitance ESR Control in D5M I/O ring
  [11:10] ACPNUMSEL rw — Address/Command custom pin mapping configuration
  [9:6] CKDCC rw — CK Duty Cycle Correction
  [5:4] ACPDRMODE rw — AC Power Down Receiver Mode
  [3:2] ACODTMODE rw — AC On-die Termination Mode
  [0] ACRANKCLKSEL rw — Control delayed or non-delayed clock to CS_N/ODT?CKE AC slices.
0x504 DDRPHY_ACIOCR1 rw — AC I/O Configuration Register 1
  [31:0] AOEMODE — SDRAM Address Output Enable (OE) Mode Selection
